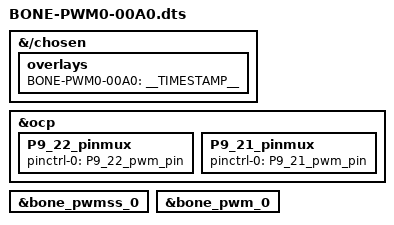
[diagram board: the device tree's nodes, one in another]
/*
 * Copyright (C) 2020 Deepak Khatri <deepaklorkhatri7@gmail.com>
 *
 * Virtual cape for /dev/bone/pwm/0 (only on BBBWL/BBB)
 *
 * This program is free software; you can redistribute it and/or modify
 * it under the terms of the GNU General Public License version 2 as
 * published by the Free Software Foundation.
 */
 
/dts-v1/;
/plugin/;

/*
* Helper to show loaded overlays under: /proc/device-tree/chosen/overlays/
*/
&{/chosen} {
    overlays {
        BONE-PWM0-00A0 = __TIMESTAMP__;
    };
};

/*
* Update the default pinmux of the pins.
*/
&ocp {
    P9_22_pinmux { pinctrl-0 = <&P9_22_pwm_pin>; };    /* PWM A */
    P9_21_pinmux { pinctrl-0 = <&P9_21_pwm_pin>; };    /* PWM B */
};

// See these files for the definition
// https://github.com/beagleboard/BeagleBoard-DeviceTrees/src/arm/bbai-bone-buses.dtsi
// https://github.com/beagleboard/BeagleBoard-DeviceTrees/src/arm/bbb-bone-buses.dtsi
&bone_pwmss_0 {
    status = "okay";
};

&bone_pwm_0 {
    status = "okay";
};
